# A31T51x register map
Vendor: ABOV Semiconductor Co., Ltd.; File version: 1.0
CPU: CM0PLUS r0p1, little endian, no MPU, no FPU, VTOR, 2 interrupt priority bits
Registers are 32-bit, read-write, reset 0x0 unless marked. A register's access mark holds for its fields unless they carry their own. Offsets are from the block's base; [hi:lo] are bit positions; {n}, {i} and the like mark numbered series.

## TOUCH0 — Touch Sensor
Base 0x40003800
Same registers: TOUCH1 0x40003A00
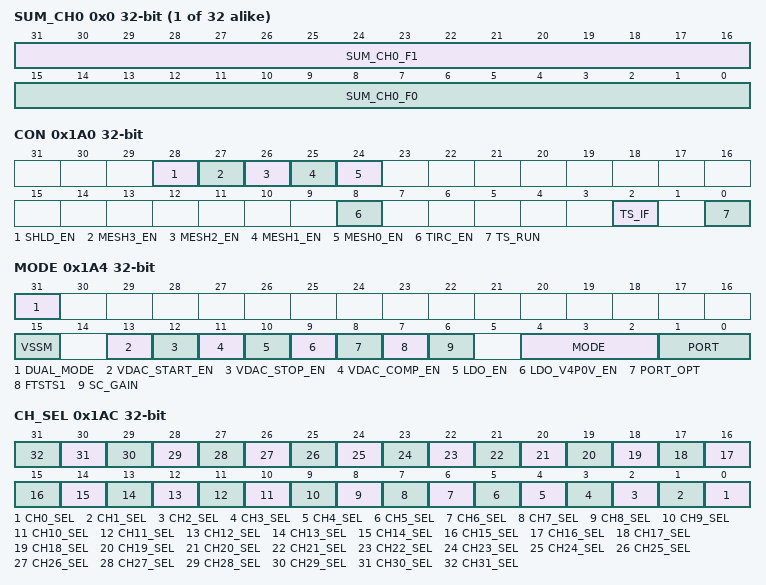
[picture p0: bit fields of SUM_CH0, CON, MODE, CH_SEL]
{0x0+4i} SUM_CH{i} (i=0..31) — Touch Sensor n Sum Register
  [31:16] SUM_CH{i}_F1 — Touch Sensor n Chx Freq1 Sum Register (n=0~1, x=0~31)
  [15:0] SUM_CH{i}_F0 — Touch Sensor n Chx Freq1 Sum Register (n=0~1, x=0~31)
{0xD0+4i} SCO{i} (i=0..31) — Touch Sensor n Offset Capacitor Selection Register
  [11:0] SCON — Touch Sensor n Chx Offset Capacitor Selection Register (n=0~1, x=0~31)
0x1A0 CON — Touch Sensor n Control Register
  [28] SHLD_EN — Shield Function enable
  [27] MESH3_EN — MESH shield CS15 channel selection
  [26] MESH2_EN — MESH shield CS9 channel selection
  [25] MESH1_EN — MESH shield CS5 channel selection
  [24] MESH0_EN — MESH shield CS1 channel selection
  [8] TIRC_EN — Touch IRC enable
    0=Disable (Touch IRC disable); 1=Enable (Touch IRC enable)
  [2] TS_IF — Touch sensor interrupt flag
  [0] TS_RUN — Touch sensor enable
    0=Disable (Touch sensor disable); 1=Enable (Touch sensor enable)
0x1A4 MODE — Touch Sensor n Mode Register
  [31] DUAL_MODE — DUAL_MODE enable
    0=Disable (Touch IRC disable); 1=Enable (Touch IRC enable)
  [15] VSSM — VSS mode selection
    0=Normal mode; 1=VSS (VSS mode)
  [13] VDAC_START_EN — Start Voltage DAC Enable
    0=Disable (Start Voltage DAC disable); 1=Enable (Start Voltage DAC enable)
  [12] VDAC_STOP_EN — Stop Voltage DAC Enable
    0=Disable (Stop Voltage DAC disable); 1=Enable (Stop Voltage DAC enable)
  [11] VDAC_COMP_EN — Comparator Reference Voltage DAC Input
    0=Disable (Comparator Reference Voltage DAC Input disable); 1=Enable (Comparator Reference Voltage DAC Input enable)
  [10] LDO_EN — LDO normal mode enable pin
    0=Disable (LDO normal mode disable); 1=Enable (LDO normal mode enable)
  [9] LDO_V4P0V_EN — LDO Output voltage Selection control pin
    0=Disable (LDO Output voltage Selection control pin disable); 1=Enable (LDO Output voltage Selection control pin enable)
  [8] PORT_OPT — Determine the channel and timing to apply PORT[1:0]. If only one channel is selected, PORT[1:0] is applied to the unselected channel. When using multiple channels, it must be set to 0.
  [7] FTSTS1 — FTSTS1 control
    0=Disable (FTSTS1 disable); 1=Enable (FTSTS1 enable)
  [6] SC_GAIN — Gain Calibration Capacitor Enable
    0=Disable (Gain Calibration Capacitor disable); 1=Enable (Gain Calibration Capacitor enable)
  [4:2] MODE — Touch sensor mode
  [1:0] PORT
0x1A8 SUM_CNT reset 0x1 — Touch Sensor n Sum Repeat Count Register
  [7:0] TS_SUM_CNT — Touch Sensor Sum Repeat Count Register
0x1AC CH_SEL — Touch Sensor n Channel Selection Register
  [n] CH{n}_SEL (n=0..31) — Channel {n} Enable
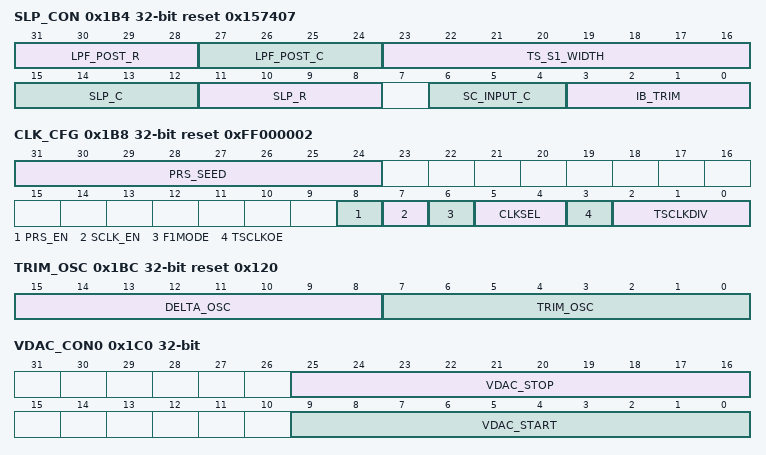
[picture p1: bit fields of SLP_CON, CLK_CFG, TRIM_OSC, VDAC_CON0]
0x1B4 SLP_CON reset 0x157407 — Touch Sensor n Low Pass Filter Control Register
  [31:28] LPF_POST_R — Comparator output LPF R
  [27:24] LPF_POST_C — Comparator output LPF C
  [23:16] TS_S1_WIDTH — S1 WIDTH = TS_S1_WIDTH * 2
  [15:12] SLP_C — Capacitor Trimming for Input Low Pass Filter
  [11:8] SLP_R — Resister Trimming for Input Low Pass Filter
  [6:4] SC_INPUT_C — Channel input noise filter cap select
  [3:0] IB_TRIM — Current Bias Trimming Value
0x1B8 CLK_CFG reset 0xFF000002 — Touch Sensor n Clock Configuration Register
  [31:24] PRS_SEED — Pseudo random Seed Data register
  [8] PRS_EN — Pseudo random touch clock enable
    0=Disable (Pseudo random touch clock disable); 1=Enable (Pseudo random touch clock enable)
  [7] SCLK_EN — Enable or disable system clock as touch clock
    0=Disable (system clock as touch clock disable); 1=Enable (system clock as touch clock enable)
  [6] F1MODE — F1 mode select
    0=2 frequence mode; 1=1 frequence mode
  [5:4] CLKSEL — Touch Clock source select
  [3] TSCLKOE — Divided Touch Sensor Clock Output Enable
    0=Disable (Clock output disable); 1=Enable (Clock output enable)
  [2:0] TSCLKDIV — Touch Sensor Clock Divider (Refer to TRIM_OSC)
    0=OSCTs_/_1; 1=OSCTs_/_2; 2=OSCTs_/_4; 3=OSCTs_/_8; 4=OSCTs_/_16; 5=OSCTs_/_32; 6=OSCTs_/_64; 7=OSCTs_/_128
0x1BC TRIM_OSC reset 0x120 — Touch Sensor n RING Oscillator Trimming Selection Register
  [15:8] DELTA_OSC — Touch Sensor RING Oscillator Delta
  [7:0] TRIM_OSC — Touch Sensor RING Oscillator Trimming Selection
0x1C0 VDAC_CON0 — Touch Sensor n Start/STOP Voltage DAC Input high Register
  [25:16] VDAC_STOP — Stop Voltage DAC Input high
  [9:0] VDAC_START — Start Voltage DAC Input high
0x1C4 VDAC_CON1 — Touch Sensor n Comparator Reference Voltage DAC Input high Register
  [9:0] VDAC_COMP — Comparator Reference Voltage DAC Input high
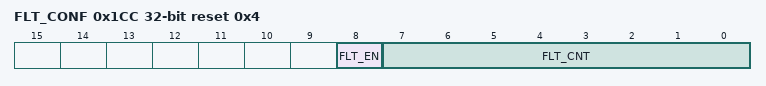
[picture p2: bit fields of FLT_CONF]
0x1CC FLT_CONF reset 0x4 — Touch Sensor n Comparator output filter configuration register
  [8] FLT_EN — Comparator filter enable
  [7:0] FLT_CNT — Digital filter count
